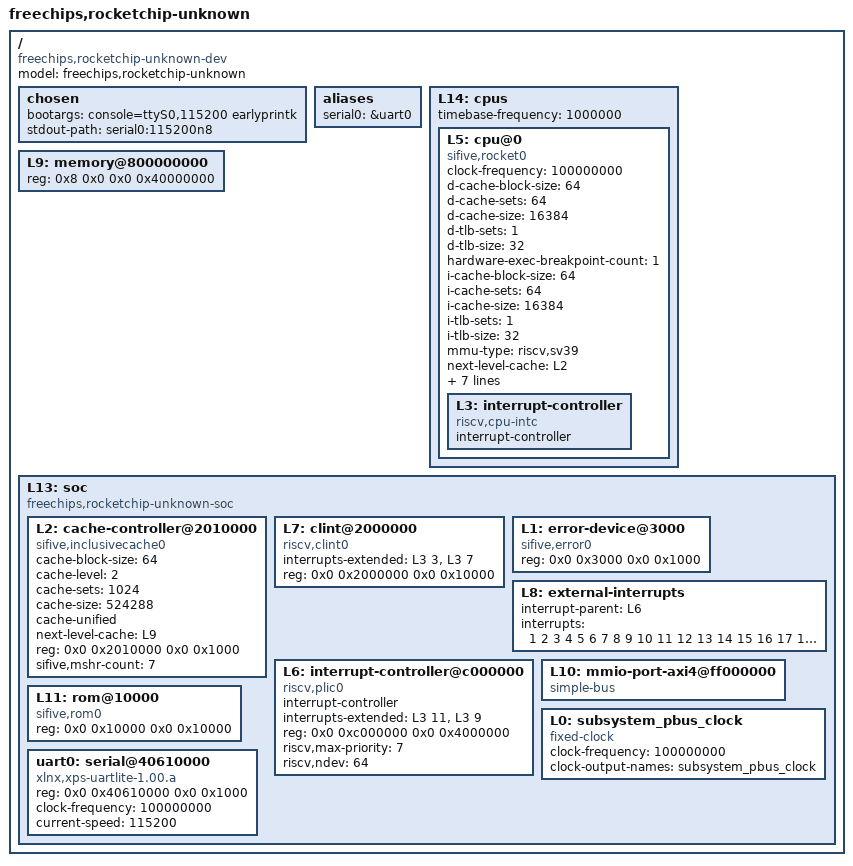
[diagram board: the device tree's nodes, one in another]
/dts-v1/;

/ {
	#address-cells = <2>;
	#size-cells = <2>;
	compatible = "freechips,rocketchip-unknown-dev";
	model = "freechips,rocketchip-unknown";

	chosen {
		bootargs = "console=ttyS0,115200 earlyprintk";
		stdout-path = "serial0:115200n8";
	};

	aliases {
		serial0 = &uart0;
	};

	L14: cpus {
		#address-cells = <1>;
		#size-cells = <0>;
		timebase-frequency = <1000000>;
		L5: cpu@0 {
			clock-frequency = <100000000>;
			compatible = "sifive,rocket0", "riscv";
			d-cache-block-size = <64>;
			d-cache-sets = <64>;
			d-cache-size = <16384>;
			d-tlb-sets = <1>;
			d-tlb-size = <32>;
			device_type = "cpu";
			hardware-exec-breakpoint-count = <1>;
			i-cache-block-size = <64>;
			i-cache-sets = <64>;
			i-cache-size = <16384>;
			i-tlb-sets = <1>;
			i-tlb-size = <32>;
			mmu-type = "riscv,sv39";
			next-level-cache = <&L2>;
			reg = <0x0>;
			riscv,isa = "rv64imafdczicsr_zifencei_zihpm_zba_zbb_zbc_zbkb_zbkc_zbkx_zbs_zknd_zkne_zknh_xrocket";
			riscv,pmpgranularity = <4>;
			riscv,pmpregions = <8>;
			status = "okay";
			timebase-frequency = <1000000>;
			tlb-split;
			L3: interrupt-controller {
				#interrupt-cells = <1>;
				compatible = "riscv,cpu-intc";
				interrupt-controller;
			};
		};
	};
	L9: memory@800000000 {
		device_type = "memory";
		reg = <0x8 0x0 0x0 0x40000000>;
	};
	L13: soc {
		#address-cells = <2>;
		#size-cells = <2>;
		compatible = "freechips,rocketchip-unknown-soc", "simple-bus";
		ranges;
		L2: cache-controller@2010000 {
			cache-block-size = <64>;
			cache-level = <2>;
			cache-sets = <1024>;
			cache-size = <524288>;
			cache-unified;
			compatible = "sifive,inclusivecache0", "cache";
			next-level-cache = <&L9>;
			reg = <0x0 0x2010000 0x0 0x1000>;
			reg-names = "control";
			sifive,mshr-count = <7>;
		};
		L7: clint@2000000 {
			compatible = "riscv,clint0";
			interrupts-extended = <&L3 3 &L3 7>;
			reg = <0x0 0x2000000 0x0 0x10000>;
			reg-names = "control";
		};
		L1: error-device@3000 {
			compatible = "sifive,error0";
			reg = <0x0 0x3000 0x0 0x1000>;
		};
		L8: external-interrupts {
			interrupt-parent = <&L6>;
			interrupts = <1 2 3 4 5 6 7 8 9 10 11 12 13 14 15 16 17 18 19 20 21 22 23 24 25 26 27 28 29 30 31 32 33 34 35 36 37 38 39 40 41 42 43 44 45 46 47 48 49 50 51 52 53 54 55 56 57 58 59 60 61 62 63 64>;
		};
		L6: interrupt-controller@c000000 {
			#interrupt-cells = <1>;
			compatible = "riscv,plic0";
			interrupt-controller;
			interrupts-extended = <&L3 11 &L3 9>;
			reg = <0x0 0xc000000 0x0 0x4000000>;
			reg-names = "control";
			riscv,max-priority = <7>;
			riscv,ndev = <64>;
		};
		L10: mmio-port-axi4@ff000000 {
			#address-cells = <1>;
			#size-cells = <1>;
			compatible = "simple-bus";
			ranges = <0x20000000 0x0 0x20000000 0xe0000000>;
		};
		L11: rom@10000 {
			compatible = "sifive,rom0";
			reg = <0x0 0x10000 0x0 0x10000>;
			reg-names = "mem";
		};
		L0: subsystem_pbus_clock {
			#clock-cells = <0>;
			clock-frequency = <100000000>;
			clock-output-names = "subsystem_pbus_clock";
			compatible = "fixed-clock";
		};
		uart0: serial@40610000 {
			compatible = "xlnx,xps-uartlite-1.00.a";
			reg = <0x0 0x40610000 0x0 0x1000>;
			clock-frequency = <100000000>;
			current-speed = <115200>;
		};
	};
};

